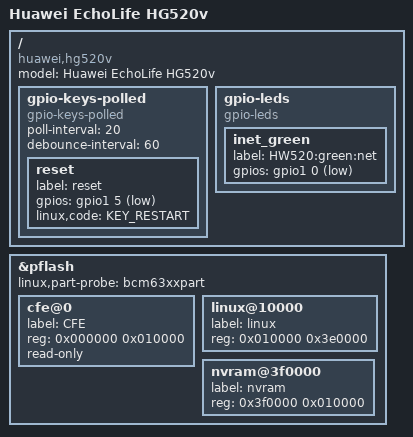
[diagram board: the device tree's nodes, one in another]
/dts-v1/;

#include "bcm6358.dtsi"

#include <dt-bindings/input/input.h>

/ {
	model = "Huawei EchoLife HG520v";
	compatible = "huawei,hg520v", "brcm,bcm6358";

	gpio-keys-polled {
		compatible = "gpio-keys-polled";
		#address-cells = <1>;
		#size-cells = <0>;
		poll-interval = <20>;
		debounce-interval = <60>;

		reset {
			label = "reset";
			gpios = <&gpio1 5 1>;
			linux,code = <KEY_RESTART>;
		};
	};

	gpio-leds {
		compatible = "gpio-leds";

		inet_green {
			label = "HW520:green:net";
			gpios = <&gpio1 0 1>;
		};
	};
};

&pflash {
	status = "ok";

	linux,part-probe = "bcm63xxpart";

	cfe@0 {
		label = "CFE";
		reg = <0x000000 0x010000>;
		read-only;
	};

	linux@10000 {
		label = "linux";
		reg = <0x010000 0x3e0000>;
	};

	nvram@3f0000 {
		label = "nvram";
		reg = <0x3f0000 0x010000>;
	};
};
